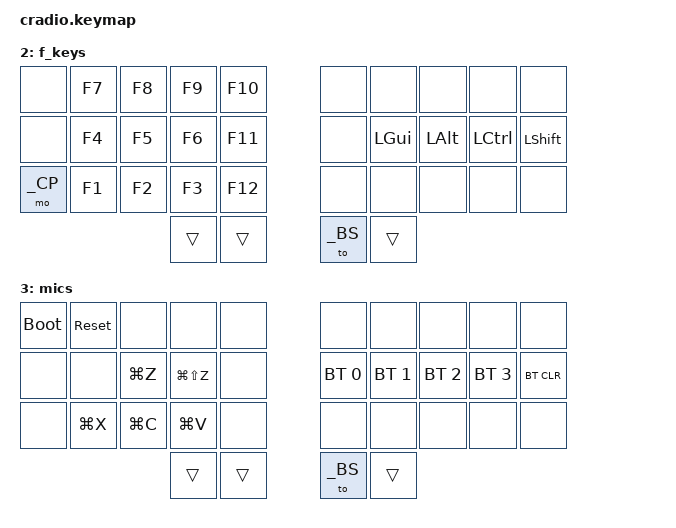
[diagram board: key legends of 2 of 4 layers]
// Copyright (c) 2022 The ZMK Contributors
// SPDX-License-Identifier: MIT

#include <behaviors.dtsi>
#include <dt-bindings/zmk/keys.h>
#include <dt-bindings/zmk/bt.h>

#define COMBO(NAME, BINDINGS, KEYPOS) \
  combo_##NAME { \
    bindings = <BINDINGS>; \
    key-positions = <KEYPOS>; \
    timeout-ms = <80>; \
  };

// Home row mods macro
#define HRML(k1,k2,k3,k4) &ht LSHFT k1 &ht LCTRL k2 &ht LALT  k3 &ht LGUI  k4
#define HRMR(k1,k2,k3,k4) &ht RGUI  k1 &ht RALT  k2 &ht RCTRL k3 &ht RSHFT k4

#define _BS 0
#define _NM 1
#define _FN 2
#define _CP 3

#define ENBS  &tl _BS ENTER
#define CPGV  &lt _CP GRAVE
#define F10GV &lt _CP F10
#define BT_0  &bt BT_SEL 0
#define BT_1  &bt BT_SEL 1
#define BT_2  &bt BT_SEL 2
#define BT_3  &bt BT_SEL 3

/ {
    behaviors {
        ht: hold_tap {
            label = "hold_tap";
            compatible = "zmk,behavior-hold-tap";
            #binding-cells = <2>;
            flavor = "tap-preferred";
            tapping-term-ms = <200>;
            quick-tap-ms = <150>;
            global-quick-tap;
            bindings = <&kp>, <&kp>;
        };

        tl: tap_layer {
            compatible = "zmk,behavior-hold-tap";
            label = "TAP_LAYER";
            #binding-cells = <2>;
            tapping_term_ms = <200>;
            quick_tap_ms = <150>;
            flavor = "tap-preferred";
            bindings = <&to>, <&kp>;
        };
    };

    macros {
        esc_bs: esc_bs {
            label = "ESC_to_BS";
            compatible = "zmk,behavior-macro";
            #binding-cells = <0>;
            bindings
                = <&macro_tap &kp ESC>
                , <&macro_tap &to _BS>
                ;
        };
    };

    combos {
/*                KEY POSITIONS

  ╭────────────────────╮ ╭────────────────────╮
  │  0   1   2   3   4 │ │  5   6   7   8   9 │
  │ 10  11  12  13  14 │ │ 15  16  17  18  19 │
  │ 20  21  22  23  24 │ │ 25  26  27  28  29 │
  ╰───────────╮ 30  31 │ │ 32  33 ╭───────────╯
              ╰────────╯ ╰────────╯            */
        compatible = "zmk,combos";

	COMBO(esc, &esc_bs, 3 6)
        // COMBO(enter, &kp ENTER, 30 33)
    };

    conditional_layers {
        compatible = "zmk,conditional-layers";
    };

    keymap {
        compatible = "zmk,keymap";
        default_layer {
            bindings = <
        //╭──────────┬──────────┬──────────┬──────────┬──────────╮   ╭──────────┬──────────┬──────────┬──────────┬──────────╮
        //│  Q       │  W       │  F       │  P       │  B       │   │  J       │  L       │  U       │  Y       │  ; :     │
            &kp Q      &kp W      &kp F      &kp P      &kp B          &kp J      &kp L      &kp U      &kp Y      &kp SEMI
        //├──────────┼──────────┼──────────┼──────────┼──────────┤   ├──────────┼──────────┼──────────┼──────────┼──────────┤
        //│  A       │  R       │  S       │  T       │  G       │   │  M       │  N       │  E       │  I       │ O        │
            HRML(A,         R,        S,         T)     &kp G          &kp M      HRMR(N,        E,         I,         O)
        //├──────────┼──────────┼──────────┼──────────┼──────────┤   ├──────────┼──────────┼──────────┼──────────┼──────────┤
        //│  Z       │  X       │  C       │  D       │  V       │   │  K       │  H       │ , <      │ . >      │ / ?      │
            &lt _CP Z  &kp X      &kp C      &kp D      &kp V          &kp K      &kp H      &kp COMMA  &kp DOT    &kp FSLH
        //╰──────────┴──────────┴──────────┼──────────┼──────────┤   ├──────────┼──────────┼──────────┴──────────┴──────────╯
        //                                 │          │          │   │          │          │
                                             &kp BSPC   &to _NM        &kp ENTER  &kp SPACE
        //                                 ╰──────────┴──────────╯   ╰──────────┴──────────╯
            >;
        };

        numbers {
            bindings = <
        //╭──────────┬──────────┬──────────┬──────────┬──────────╮   ╭──────────┬──────────┬──────────┬──────────┬──────────╮
        //│          │  7       │  8       │  9       │  0       │   │          │          │          │          │          │
            &esc_bs    &kp N7     &kp N8     &kp N9     &kp N0         &kp LBKT   &kp RBKT   &kp LBRC   &kp RBRC   &kp BSLH         
        //├──────────┼──────────┼──────────┼──────────┼──────────┤   ├──────────┼──────────┼──────────┼──────────┼──────────┤
        //│ ' "      │  4       │  5       │  6       │  - _     │   │          │          │          │          │          │
            HRML(SQT,      N4,        N5,        N6)    &kp MINUS      &kp TAB    HRMR(LEFT, DOWN,      UP,        RIGHT)
        //├──────────┼──────────┼──────────┼──────────┼──────────┤   ├──────────┼──────────┼──────────┼──────────┼──────────┤
        //│  ` ~     │  1       │  2       │  3       │  = +     │   │          │          │          │          │          │
            CPGV       &kp N1     &kp N2     &kp N3     &kp EQUAL      &caps_word &kp UNDER  &trans     &trans     &to _FN
        //╰──────────┴──────────┴──────────┼──────────┼──────────┤   ├──────────┼──────────┼──────────┴──────────┴──────────╯
        //                                 │          │          │   │          │          │
                                             &trans     &trans         &to _BS    &trans 
        //                                 ╰──────────┴──────────╯   ╰──────────┴──────────╯
            >;
        };
        
        f_keys {
            bindings = <
        //╭──────────┬──────────┬──────────┬──────────┬──────────╮   ╭──────────┬──────────┬──────────┬──────────┬──────────╮
        //│          │  F7      │  F8      │  F9      │          │   │          │          │          │          │          │
            &none      &kp F7     &kp F8     &kp F9     &kp F10        &none      &none      &none      &none      &none
        //├──────────┼──────────┼──────────┼──────────┼──────────┤   ├──────────┼──────────┼──────────┼──────────┼──────────┤
        //│          │  F4      │  F5      │  F6      │          │   │          │          │          │          │          │
            &none      &kp F4     &kp F5     &kp F6     &kp F11        &none      &kp LGUI   &kp LALT   &kp LCTL   &kp LSHFT
        //├──────────┼──────────┼──────────┼──────────┼──────────┤   ├──────────┼──────────┼──────────┼──────────┼──────────┤
        //│          │  F1      │  F2      │  F3      │          │   │          │          │          │          │          │
            &mo _CP    &kp F1     &kp F2     &kp F3     &kp F12        &none      &none      &none      &none      &none
        //╰──────────┴──────────┴──────────┼──────────┼──────────┤   ├──────────┼──────────┼──────────┴──────────┴──────────╯
        //                                 │          │          │   │          │          │
                                             &trans     &trans         &to _BS    &trans 
        //                                 ╰──────────┴──────────╯   ╰──────────┴──────────╯
            >;
        };

        mics {
            bindings = <
        //╭──────────┬──────────┬──────────┬──────────┬──────────╮   ╭──────────┬──────────┬──────────┬──────────┬──────────╮
        //│          │          │          │          │          │   │          │          │          │          │          │
          &bootloader &sys_reset  &none      &none      &none          &none      &none      &none      &none      &none
        //├──────────┼──────────┼──────────┼──────────┼──────────┤   ├──────────┼──────────┼──────────┼──────────┼──────────┤
        //│          │          │          │          │          │   │          │          │          │          │          │
            &none      &none      &kp LG(Z)  &kp LG(LS(Z)) &none       BT_0       BT_1       BT_2       BT_3       &bt BT_CLR
        //├──────────┼──────────┼──────────┼──────────┼──────────┤   ├──────────┼──────────┼──────────┼──────────┼──────────┤
        //│          │          │          │          │          │   │          │          │          │          │          │
            &none      &kp LG(X)  &kp LG(C)  &kp LG(V)  &none          &none      &none      &none      &none      &none
        //╰──────────┴──────────┴──────────┼──────────┼──────────┤   ├──────────┼──────────┼──────────┴──────────┴──────────╯
        //                                 │          │          │   │          │          │
                                             &trans     &trans         &to _BS    &trans 
        //                                 ╰──────────┴──────────╯   ╰──────────┴──────────╯
            >;
        };
    };
};
